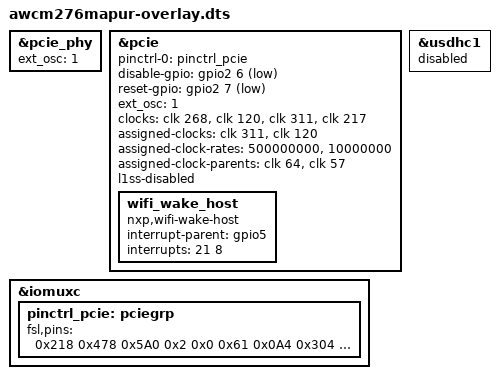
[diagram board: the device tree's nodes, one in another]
// SPDX-License-Identifier: (GPL-2.0+ OR MIT)
/*
 * Copyright 2023 ADLINK Technology Corp.
 *
 * Author: Po Cheng <po.cheng@adlinktech.com>
 */

/dts-v1/;
/plugin/;

/ {
	fragment@0 {
		target = <&pcie_phy>;
		__overlay__ {
			ext_osc = <1>;
			status = "okay";
		};
	};

	fragment@1 {
		target = <&pcie>;
		__overlay__ {
			pinctrl-names = "default";
			pinctrl-0 = <&pinctrl_pcie>;
			disable-gpio = <&gpio2 6 1>;  /* GPIO_ACTIVE_LOW = 1 */
			reset-gpio = <&gpio2 7 1>;  /* GPIO_ACTIVE_LOW = 1 */
			ext_osc = <1>;
			clocks = <&clk 268>, /* IMX8MP_CLK_HSIO_ROOT = 268 */
					<&clk 120>, /* IMX8MP_CLK_PCIE_AUX = 120 */
					<&clk 311>, /* IMX8MP_CLK_HSIO_AXI = 311 */
					<&clk 217>; /* IMX8MP_CLK_PCIE_ROOT = 217 */
			clock-names = "pcie", "pcie_aux", "pcie_phy", "pcie_bus";
			assigned-clocks = <&clk 311>, /* IMX8MP_CLK_HSIO_AXI = 311 */
							<&clk 120>; /* IMX8MP_CLK_PCIE_AUX = 120 */
			assigned-clock-rates = <500000000>, <10000000>;
			assigned-clock-parents = <&clk 64>, /* IMX8MP_SYS_PLL2_500M = 64 */
									<&clk 57>; /* IMX8MP_SYS_PLL2_50M = 57 */
			l1ss-disabled;
			status = "okay";

			wifi_wake_host {
				compatible = "nxp,wifi-wake-host";
				interrupt-parent = <&gpio5>;
				interrupts = <21 8>;  /* IRQ_TYPE_LEVEL_LOW = 8 */
				interrupt-names = "host-wake";
			};
		};
	};

	fragment@2 {
		target = <&iomuxc>;
		__overlay__ {
			pinctrl_pcie: pciegrp {
				fsl,pins = <
					/* MX8MP_IOMUXC_I2C4_SCL__PCIE_CLKREQ_B - open drain, pull up */
					0x218 0x478 0x5A0 0x2 0x0	0x61
					/* MX8MP_IOMUXC_SD1_DATA4__GPIO2_IO06 - PCIe disable */
					0x0A4 0x304 0x000 0x5 0x0	0x41
					/* MX8MP_IOMUXC_SD1_DATA5__GPIO2_IO07 - PCIe Reset */
					0x0A8 0x308 0x000 0x5 0x0	0x41
					/* MX8MP_IOMUXC_I2C4_SDA__GPIO5_IO21 - PCIe Wakeup */
					0x21C 0x47C 0x000 0x5 0x0	0x1c4
				>;
			};
		};
	};

	fragment@3 {
		target = <&usdhc1>;
		__overlay__ {
			status = "disabled";
		};
	};
};

